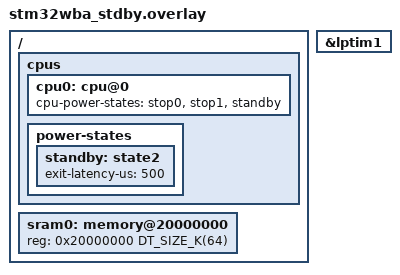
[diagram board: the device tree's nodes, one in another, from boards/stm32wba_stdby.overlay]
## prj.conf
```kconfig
CONFIG_BT=y
CONFIG_LOG=y
CONFIG_BT_SMP=y
CONFIG_BT_PERIPHERAL=y
CONFIG_BT_DIS=y
CONFIG_BT_DIS_PNP=n
CONFIG_BT_BAS=y
CONFIG_BT_HRS=y
CONFIG_BT_DEVICE_NAME="Zephyr Heartrate Sens"
CONFIG_BT_DEVICE_APPEARANCE=833

# Disable UART driver
#CONFIG_SERIAL=n

# Disable Console
#CONFIG_CONSOLE=n
#CONFIG_UART_CONSOLE=n
```

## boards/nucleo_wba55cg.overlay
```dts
/*
 * SPDX-License-Identifier: Apache-2.0
 *
 * Copyright (c) 2023 STMicroelectronics
 */

/ {
	/* Change min residency time to ease power consumption measurement */
	cpus {
		cpu0: cpu@0 {
			cpu-power-states = <&stop0 &stop1 &standby>;
		};

		power-states {
			standby: state2 {
				compatible = "zephyr,power-state";
				power-state-name = "suspend-to-ram";
				substate-id = <1>;
				min-residency-us = <10000>;
				exit-latency-us = <1000>;
			};
		};
	};
#if 0
	swj_port: swj_port {
		compatible = "swj-connector";
		/delete-node/ pinctrl-1;
		/delete-property/ pinctrl-1;
		pinctrl-0 = <&debug_jtms_swdio_pa13 &debug_jtck_swclk_pa14
			 &debug_jtdi_pa15 &debug_jtdo_swo_pb3
			 &debug_njtrst_pb4>;
		pinctrl-names = "default";
	};
#endif

};

&lptim1 {
	status = "okay";
};
```

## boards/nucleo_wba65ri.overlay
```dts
/*
 * SPDX-License-Identifier: Apache-2.0
 *
 * Copyright (c) 2023 STMicroelectronics
 */

/ {
	/* Change min residency time to ease power consumption measurement */
	cpus {
		cpu0: cpu@0 {
			cpu-power-states = <&stop0 &stop1 &standby>;
		};

		power-states {
			standby: state2 {
				compatible = "zephyr,power-state";
				power-state-name = "suspend-to-ram";
				substate-id = <1>;
				min-residency-us = <10000>;
				exit-latency-us = <1000>;
			};
		};
	};
#if 0
	swj_port: swj_port {
		compatible = "swj-connector";
		/delete-node/ pinctrl-1;
		/delete-property/ pinctrl-1;
		pinctrl-0 = <&debug_jtms_swdio_pa13 &debug_jtck_swclk_pa14
			 &debug_jtdi_pa15 &debug_jtdo_swo_pb3
			 &debug_njtrst_pb4>;
		pinctrl-names = "default";
	};
#endif
};

&lptim1 {
	status = "okay";
};
```

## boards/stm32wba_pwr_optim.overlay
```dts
/*
 * SPDX-License-Identifier: Apache-2.0
 *
 * Copyright (c) 2025 STMicroelectronics
 */
/ {
	/* Change min residency time to ease power consumption measurement */
	cpus {
		cpu0: cpu@0 {
			cpu-power-states = <&stop0 &stop1 &standby>;
		};
	};
};

&pwr {
	standby-exit-latency-profiling;
	standby-exit-latency-initial-us = <1500>;
};

/*
 * Reduce flash usage for the power-optimized setup so the full flash is
 * not used when it is not necessary, helping reduce power consumption.
 * the pm_S2ram node is moved accordingly to the end of the used flash.
 */
&sram0 {
	reg = <0x20000000 (DT_SIZE_K(64) - 0x20)>;
};

&pm_s2ram {
	reg = <(0x20000000 + DT_SIZE_K(64) - 0x20) 0x20>;
};
```

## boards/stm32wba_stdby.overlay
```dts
/*
 * SPDX-License-Identifier: Apache-2.0
 *
 * Copyright (c) 2025 STMicroelectronics
 */
/ {
	/* Change min residency time to ease power consumption measurement */
	cpus {
		cpu0: cpu@0 {
			cpu-power-states = <&stop0 &stop1 &standby>;
		};

		power-states {
			standby: state2 {
				exit-latency-us = <500>;
			};
		};
	};

	sram0: memory@20000000 {
		reg = <0x20000000 DT_SIZE_K(64)>;
	};
};

&lptim1 {
	status = "okay";
};
```

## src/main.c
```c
/* main.c - Application main entry point */

/*
 * Copyright (c) 2024 Nordic Semiconductor ASA
 * Copyright (c) 2015-2016 Intel Corporation
 *
 * SPDX-License-Identifier: Apache-2.0
 */

#include <zephyr/device.h>
#include <zephyr/devicetree.h>

#include <zephyr/bluetooth/bluetooth.h>
#include <zephyr/bluetooth/hci.h>
#include <zephyr/bluetooth/conn.h>
#include <zephyr/bluetooth/uuid.h>
#include <zephyr/bluetooth/gatt.h>
#include <zephyr/bluetooth/services/bas.h>
#include <zephyr/bluetooth/services/hrs.h>
#include <zephyr/net_buf.h>

#define BT_GAP_ADV_1280MS  0x0800   /* 1280 ms */

#define BT_LE_ADV_CONN_1280MS \
	BT_LE_ADV_PARAM(BT_LE_ADV_OPT_CONN, BT_GAP_ADV_1280MS, BT_GAP_ADV_1280MS, NULL)

static bool hrf_ntf_enabled;

#if 0
	BT_DATA_BYTES(BT_DATA_FLAGS, (BT_LE_AD_GENERAL | BT_LE_AD_NO_BREDR)),
	BT_DATA_BYTES(BT_DATA_MANUFACTURER_DATA, 0x01, 0x02),
#endif


static const struct bt_data ad[] = {
	BT_DATA_BYTES(BT_DATA_FLAGS, (BT_LE_AD_GENERAL | BT_LE_AD_NO_BREDR)),
	BT_DATA_BYTES(BT_DATA_UUID16_ALL,
		      BT_UUID_16_ENCODE(BT_UUID_HRS_VAL),
		      BT_UUID_16_ENCODE(BT_UUID_BAS_VAL),
		      BT_UUID_16_ENCODE(BT_UUID_DIS_VAL)),
#if defined(CONFIG_BT_EXT_ADV)
	BT_DATA(BT_DATA_NAME_COMPLETE, CONFIG_BT_DEVICE_NAME, sizeof(CONFIG_BT_DEVICE_NAME) - 1),
#endif /* CONFIG_BT_EXT_ADV */
};

#if !defined(CONFIG_BT_EXT_ADV)
static const struct bt_data sd[] = {
	BT_DATA(BT_DATA_NAME_COMPLETE, CONFIG_BT_DEVICE_NAME, sizeof(CONFIG_BT_DEVICE_NAME) - 1),
};
#endif /* !CONFIG_BT_EXT_ADV */

enum {
	STATE_CONNECTED,
	STATE_DISCONNECTED,

	STATE_BITS,
};

static ATOMIC_DEFINE(state, STATE_BITS);

static void connected(struct bt_conn *conn, uint8_t err)
{
	if (err) {
		printk("Connection failed, err 0x%02x %s\n", err, bt_hci_err_to_str(err));
	} else {
		printk("Connected\n");

		(void)atomic_set_bit(state, STATE_CONNECTED);
	}
}

static void disconnected(struct bt_conn *conn, uint8_t reason)
{
	printk("Disconnected, reason 0x%02x %s\n", reason, bt_hci_err_to_str(reason));

	(void)atomic_set_bit(state, STATE_DISCONNECTED);
}

BT_CONN_CB_DEFINE(conn_callbacks) = {
	.connected = connected,
	.disconnected = disconnected,
};

static void hrs_ntf_changed(bool enabled)
{
	hrf_ntf_enabled = enabled;

	printk("HRS notification status changed: %s\n",
	       enabled ? "enabled" : "disabled");
}

static struct bt_hrs_cb hrs_cb = {
	.ntf_changed = hrs_ntf_changed,
};

static void auth_cancel(struct bt_conn *conn)
{
	printk("Pairing cancelled: %s\n", bt_conn_dst_str(conn));
}

static struct bt_conn_auth_cb auth_cb_display = {
	.cancel = auth_cancel,
};

static void get_adv_tx_power(void)
{
	struct net_buf *rsp = NULL;
	struct bt_hci_rp_le_read_chan_tx_power *rp;
	int err;

	err = bt_hci_cmd_send_sync(BT_HCI_OP_LE_READ_ADV_CHAN_TX_POWER, NULL, &rsp);
	if (err) {
		printk("Reading advertising TX power failed (err %d)\n", err);
		return;
	}

	rp = (void *)rsp->data;
	printk("Getting advertising TX power: %d dBm\n", rp->tx_power_level);

	net_buf_unref(rsp);
}
/*
 * Set advertising TX power
 * using proprietary command ACI_HAL_SET_TX_POWER_LEVEL
 * opcode, input and output parameters are described in the ST wireless interface documentation
 * opcode = 0xFC0F
 * See also modules\hal\stm32\lib\stm32wba\STM32_WPAN\ble\stack\include\auto\ble_types.h for type definitions.
 */

#define ACI_HAL_SET_TX_POWER_LEVEL       BT_OP(BT_OGF_VS, 0xFC0F)

struct aci_set_tx_power_cp {
  uint8_t En_High_Power;
  uint8_t PA_Level;
};

static void set_adv_tx_power(uint8_t tx_power)
{
	struct aci_set_tx_power_cp *cp;
	struct net_buf *buf, *rsp;
	int err;

	/* Immediate HCI command creation */
	buf = bt_hci_cmd_alloc(K_NO_WAIT);
	if (!buf) {
	    printk("bt_hci_cmd_alloc failed with -NOBUFS \n");
	}

	/* Adding space for command parameters */
	cp = net_buf_add(buf, sizeof(*cp));

	/* Filling parameters */
	cp->En_High_Power = 0x01; /* Required, but ignored by the controller */
	cp->PA_Level = tx_power;

	/* Sending the command */
	err = bt_hci_cmd_send_sync(ACI_HAL_SET_TX_POWER_LEVEL, buf, &rsp);
	if (err) {
		printk("Setting advertising TX power failed (err %d)\n", err);
	}
	net_buf_unref(rsp);
}


static void bas_notify(void)
{
	uint8_t battery_level = bt_bas_get_battery_level();

	battery_level--;

	if (!battery_level) {
		battery_level = 100U;
	}

	bt_bas_set_battery_level(battery_level);
}

static void hrs_notify(void)
{
	static uint8_t heartrate = 90U;

	/* Heartrate measurements simulation */
	heartrate++;
	if (heartrate == 160U) {
		heartrate = 90U;
	}

	if (hrf_ntf_enabled) {
		bt_hrs_notify(heartrate);
	}
}

#if defined(CONFIG_GPIO)
/* The devicetree node identifier for the "led0" alias. */
#define LED0_NODE DT_ALIAS(led0)

#if DT_NODE_HAS_STATUS_OKAY(LED0_NODE)
#include <zephyr/drivers/gpio.h>
#define HAS_LED     1
static const struct gpio_dt_spec led = GPIO_DT_SPEC_GET(LED0_NODE, gpios);
#define BLINK_ONOFF K_MSEC(500)

static struct k_work_delayable blink_work;
static bool                  led_is_on;

static void blink_timeout(struct k_work *work)
{
	led_is_on = !led_is_on;
	gpio_pin_set(led.port, led.pin, (int)led_is_on);

	k_work_schedule(&blink_work, BLINK_ONOFF);
}

static int blink_setup(void)
{
	int err;

	printk("Checking LED device...");
	if (!gpio_is_ready_dt(&led)) {
		printk("failed.\n");
		return -EIO;
	}
	printk("done.\n");

	printk("Configuring GPIO pin...");
	err = gpio_pin_configure_dt(&led, GPIO_OUTPUT_ACTIVE);
	if (err) {
		printk("failed.\n");
		return -EIO;
	}
	printk("done.\n");

	k_work_init_delayable(&blink_work, blink_timeout);

	return 0;
}

static void blink_start(void)
{
	printk("Start blinking LED...\n");
	led_is_on = false;
	gpio_pin_set(led.port, led.pin, (int)led_is_on);
	k_work_schedule(&blink_work, BLINK_ONOFF);
}

static void blink_stop(void)
{
	struct k_work_sync work_sync;

	printk("Stop blinking LED.\n");
	k_work_cancel_delayable_sync(&blink_work, &work_sync);

	/* Keep LED on */
	led_is_on = true;
	gpio_pin_set(led.port, led.pin, (int)led_is_on);
}
#endif /* LED0_NODE */
#endif /* CONFIG_GPIO */

int main(void)
{
	int err;

	err = bt_enable(NULL);
	if (err) {
		printk("Bluetooth init failed (err %d)\n", err);
		return 0;
	}

	printk("Bluetooth initialized\n");

	bt_conn_auth_cb_register(&auth_cb_display);

	bt_hrs_cb_register(&hrs_cb);

	get_adv_tx_power();
	printk("Setting Advertising TX power to 0 dBm\n");
	set_adv_tx_power(0x19);
	get_adv_tx_power();

#if !defined(CONFIG_BT_EXT_ADV)
	printk("Starting Legacy Advertising (connectable and scannable)\n");
	err = bt_le_adv_start(BT_LE_ADV_CONN_1280MS, ad, ARRAY_SIZE(ad), sd, ARRAY_SIZE(sd));
	if (err) {
		printk("Advertising failed to start (err %d)\n", err);
		return 0;
	}

#else /* CONFIG_BT_EXT_ADV */
	struct bt_le_adv_param adv_param = {
		.id = BT_ID_DEFAULT,
		.sid = 0U,
		.secondary_max_skip = 0U,
		.options = (BT_LE_ADV_OPT_EXT_ADV | BT_LE_ADV_OPT_CONN | BT_LE_ADV_OPT_CODED),
		.interval_min = BT_GAP_ADV_FAST_INT_MIN_2,
		.interval_max = BT_GAP_ADV_FAST_INT_MAX_2,
		.peer = NULL,
	};
	struct bt_le_ext_adv *adv;

	printk("Creating a Coded PHY connectable non-scannable advertising set\n");
	err = bt_le_ext_adv_create(&adv_param, NULL, &adv);
	if (err) {
		printk("Failed to create Coded PHY extended advertising set (err %d)\n", err);

		printk("Creating a non-Coded PHY connectable non-scannable advertising set\n");
		adv_param.options &= ~BT_LE_ADV_OPT_CODED;
		err = bt_le_ext_adv_create(&adv_param, NULL, &adv);
		if (err) {
			printk("Failed to create extended advertising set (err %d)\n", err);
			return 0;
		}
	}

	printk("Setting extended advertising data\n");
	err = bt_le_ext_adv_set_data(adv, ad, ARRAY_SIZE(ad), NULL, 0);
	if (err) {
		printk("Failed to set extended advertising data (err %d)\n", err);
		return 0;
	}

	printk("Starting Extended Advertising (connectable non-scannable)\n");
	err = bt_le_ext_adv_start(adv, BT_LE_EXT_ADV_START_DEFAULT);
	if (err) {
		printk("Failed to start extended advertising set (err %d)\n", err);
		return 0;
	}
#endif /* CONFIG_BT_EXT_ADV */

	printk("Advertising successfully started\n");

#if defined(HAS_LED)
	err = blink_setup();
	if (err) {
		return 0;
	}

	blink_start();
#endif /* HAS_LED */

	/* Implement notification. */
	while (1) {
		k_sleep(K_SECONDS(200));

		/* Heartrate measurements simulation */
		hrs_notify();

		/* Battery level simulation */
		bas_notify();

		if (atomic_test_and_clear_bit(state, STATE_CONNECTED)) {
			/* Connected callback executed */

#if defined(HAS_LED)
			blink_stop();
#endif /* HAS_LED */
		} else if (atomic_test_and_clear_bit(state, STATE_DISCONNECTED)) {
#if !defined(CONFIG_BT_EXT_ADV)
			printk("Starting Legacy Advertising (connectable and scannable)\n");
			err = bt_le_adv_start(BT_LE_ADV_CONN_1280MS, ad, ARRAY_SIZE(ad), sd,
					      ARRAY_SIZE(sd));
			if (err) {
				printk("Advertising failed to start (err %d)\n", err);
				return 0;
			}

#else /* CONFIG_BT_EXT_ADV */
			printk("Starting Extended Advertising (connectable and non-scannable)\n");
			err = bt_le_ext_adv_start(adv, BT_LE_EXT_ADV_START_DEFAULT);
			if (err) {
				printk("Failed to start extended advertising set (err %d)\n", err);
				return 0;
			}
#endif /* CONFIG_BT_EXT_ADV */

#if defined(HAS_LED)
			blink_start();
#endif /* HAS_LED */
		}
	}

	return 0;
}
```

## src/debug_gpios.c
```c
/*
 * Copyright (c) 2025 STMicroelectronics
 *
 * SPDX-License-Identifier: Apache-2.0
 */

#include <zephyr/debug_gpios.h>

const struct gpio_dt_spec debug_gpios[DEBUG_GPIO_COUNT] = {
	GPIO_DT_SPEC_GET(DEBUG1_NODE, gpios),
	GPIO_DT_SPEC_GET(DEBUG2_NODE, gpios),
	GPIO_DT_SPEC_GET(DEBUG3_NODE, gpios),
	GPIO_DT_SPEC_GET(DEBUG4_NODE, gpios),
	GPIO_DT_SPEC_GET(DEBUG5_NODE, gpios),
	GPIO_DT_SPEC_GET(DEBUG6_NODE, gpios),
	GPIO_DT_SPEC_GET(DEBUG7_NODE, gpios),
	GPIO_DT_SPEC_GET(DEBUG8_NODE, gpios),
	GPIO_DT_SPEC_GET(DEBUG9_NODE, gpios),
	GPIO_DT_SPEC_GET(DEBUG11_NODE, gpios),
	GPIO_DT_SPEC_GET(DEBUG14_NODE, gpios),
	GPIO_DT_SPEC_GET(DEBUG15_NODE, gpios),
	GPIO_DT_SPEC_GET(DEBUG16_NODE, gpios),
};

int init_debug_gpios(void)
{
	int ret = 0;

	for (uint8_t i=0; i<DEBUG_GPIO_COUNT; i++) {
		if (!gpio_is_ready_dt(&debug_gpios[i])) {
			printk("debug GPIO %d: gpio_is_ready_dt KO!!\n", i);
			return -ENODEV;
		}
		ret = gpio_pin_configure_dt(&debug_gpios[i], GPIO_OUTPUT_INACTIVE);
		if (ret < 0) {
			printk("debug GPIO %d: gpio_pin_configure_dt KO!!\n", i);
			return ret;
		}
	}

	return 0;
}

int set_debug_gpio(uint8_t gpio_number, int value)
{
	if (gpio_number > DEBUG_GPIO_COUNT) {
		return -EINVAL;
	}

	return gpio_pin_set_dt(&debug_gpios[gpio_number - 1], value);
}

int toggle_debug_gpio(uint8_t gpio_number)
{
	if (gpio_number > DEBUG_GPIO_COUNT) {
		return -EINVAL;
	}

	return gpio_pin_toggle_dt(&debug_gpios[gpio_number - 1]);
}
```
